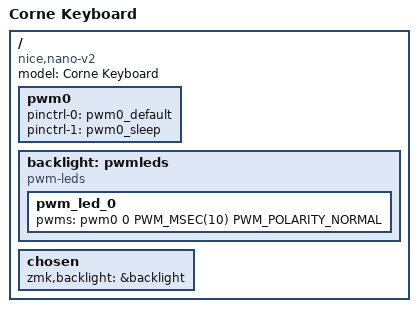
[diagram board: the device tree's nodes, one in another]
/dts-v1/;  // Device Tree 버전 명시

#include "nice_nano.dtsi"  // 필요한 .dtsi 파일 포함

/ {
    compatible = "nice,nano-v2";  // 이 부분에 해당 보드 이름 입력
    model = "Corne Keyboard";

    // PWM 설정
    pwm0 {
        status = "okay";
        pinctrl-0 = <&pwm0_default>;
        pinctrl-1 = <&pwm0_sleep>;
        pinctrl-names = "default", "sleep";
    };

    // 백라이트 설정
    backlight: pwmleds {
        compatible = "pwm-leds";
        pwm_led_0 {
            pwms = <&pwm0 0 PWM_MSEC(10) PWM_POLARITY_NORMAL>;
        };
    };

    // 선택된 노드
    chosen {
        zmk,backlight = &backlight;
    };
};
